# RTS5918 register map
Vendor: Realtek Semiconductor Corp.; Series: RTS5918 Series; File version: 1.00
CPU: ARMV8MML r0p0, little endian, MPU, FPU, VTOR, 3 interrupt priority bits, 8 SAU regions
Registers are 32-bit, read-write, reset 0x0 unless marked. A register's access mark holds for its fields unless they carry their own. Offsets are from the block's base; [hi:lo] are bit positions; {n}, {i} and the like mark numbered series.

## WDT — WDT Controller
Base 0x40253F00
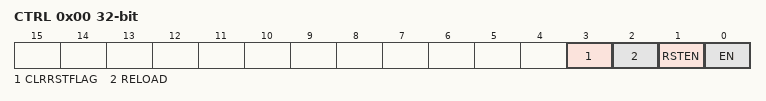
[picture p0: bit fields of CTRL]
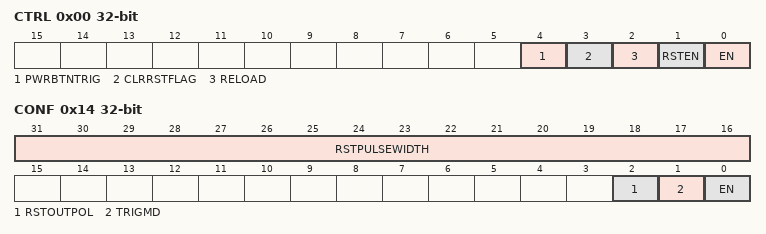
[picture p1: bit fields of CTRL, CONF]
0x00 CTRL — CONTROL REGISTER
  [3] CLRRSTFLAG write-1-clears — Clear WDT reset flag
    0=DO_NOTHING; 1=CLR (Clear WDT reset flag)
  [2] RELOAD — Reload WDT Counter
    0=DO_NOTHING; 1=RELOAD (Reload WDT counter)
  [1] RSTEN — Enable WDT to Reset System
    0=DISABLE (Disable WDT to reset system); 1=ENABLE (Enable WDT to reset system)
  [0] EN — Enable WDT
    0=DISABLE (Disable WDT); 1=ENABLE (Enable WDT)
0x04 STS ro — STATUS REGISTER
  [0] RSTFLAG — Reset Flag
    0=NOT_OCCURRED (WDT reset is not occurred); 1=OCCURRED (WDT reset is occurred)
0x08 CNT — INITIAL COUNTER REGISTER
0x0C DIV — DIVIDER REGISTER
0x10 INTEN — INTERRUPT ENABLE REGISTER
  [0] WDTINTEN — Enable WDT Interrupt
    0=DISBLE (Disable WDT interrupt); 1=ENABLE (Enable WDT interrupt)

## PWRBTN — Power Button Over WDT Controller
Base 0x4000C014
0x00 CTRL — CONTROL REGISTER
  [4] PWRBTNTRIG write-1-clears — Pwrbtn trigger status
    0=DO_NOTHING; 1=CLR (Clear PWRBTN trigger)
  [3] CLRRSTFLAG write-1-clears — Clear WDT reset flag
    0=DO_NOTHING; 1=CLR (Clear WDT reset flag)
  [2] RELOAD — Reload WDT Counter
    0=DO_NOTHING; 1=RELOAD (Reload WDT counter)
  [1] RSTEN — Enable WDT to Reset System
    0=DISABLE (Disable WDT to reset system); 1=ENABLE (Enable WDT to reset system)
  [0] EN — Enable WDT
    0=DISABLE (Disable WDT); 1=ENABLE (Enable WDT)
0x04 STS ro — STATUS REGISTER
  [0] RSTFLAG — Reset Flag
    0=NOT_OCCURRED (WDT reset is not occurred); 1=OCCURRED (WDT reset is occurred)
0x08 CNT — INITIAL COUNTER REGISTER
  [7:0] CNT — Counter value
0x0C DIV — DIVIDER REGISTER
  [15:0] DIV — Divider value
0x10 INTEN — INTERRUPT ENABLE REGISTER
  [0] WDTINTEN — Enable WDT Interrupt
    0=DISBLE (Disable WDT interrupt); 1=ENABLE (Enable WDT interrupt)
0x14 CONF — PWRBTN CONTROL REGISTER
  [31:16] RSTPULSEWIDTH — Reset Output Pulse Width
  [2] RSTOUTPOL — Reset Output Polarity
    0=LOW (Active low); 1=HIGH (Active high)
  [1] TRIGMD — Trigger Level Selection
    0=LOW (Low-level trigger); 1=HIGH (High-level trigger)
  [0] EN — Enable Power Button Function
    0=DISBLE (Disable power button function); 1=ENABLE (Enable power button function)

## SLWTMR0 — 32-bit SlowTimer Controller
Base 0x40253700
Same registers: TMR0 0x40253100, TMR1 0x40253200, TMR2 0x40253300, TMR3 0x40253400, TMR4 0x40253500, TMR5 0x40253600, SLWTMR1 0x40253800, SLWTMR2 0x40253900, SLWTMR3 0x40253A00, RTMR 0x40253B00
0x00 LDCNT — LOAD COUNTER REGISTER
0x04 CNT — CURRENT COUNTER REGISTER
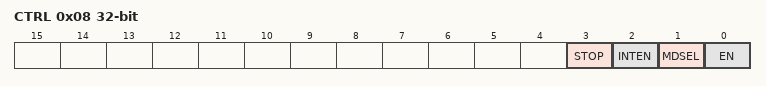
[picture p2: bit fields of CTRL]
0x08 CTRL — CONTROL REGISTER
  [3] STOP — Stop Timer
    0=DISABLE (Start timer); 1=ENABLE (Stop timer)
  [2] INTEN — Enable Timer Interrupt
    0=DISABLE (Disable timer interrupt); 1=ENABLE (Enable timer interrupt)
  [1] MDSEL — Timer Operating Mode Selection
    0=ONE_SHOT (Timer is operate at one-shot mode); 1=CONTINUOUS (Timer is operate at continuous mode)
  [0] EN — Enable Timer Contoller
    0=DISABLE (Disable timer controller); 1=ENABLE (Enable timer controller)
0x0C INTSTS — INTERRUPT STATUS REGISTER
  [0] STS write-1-clears — Timer Interrupt Status
    0=NOT_OCCURRED (Timer interrupt is not occurred); 1=OCCURRED (Timer interrupt is occurred)

## PWM0 — PWM Controller
Base 0x40254500
Same registers: PWM{n} {0x40254500+0x100*n} (n=1..13)
0x00 DUTY — PWM DUTY REGISTER
0x04 DIV — PWM DIVIDER REGISTER
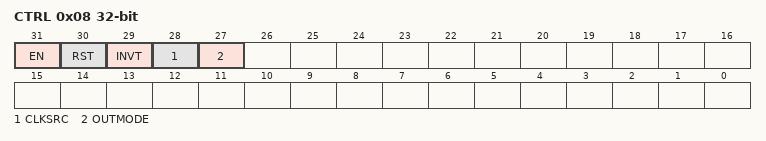
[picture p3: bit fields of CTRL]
0x08 CTRL — PWM CONTROL REGISTER
  [31] EN — Enable PWM Controller
    0=DISABLE (Disable PWM Controller); 1=ENABLE (Enable PWM Controller)
  [30] RST — Reset PWM Controller
    0=DO_NOTHING; 1=RESET (Reset PWM controller)
  [29] INVT — Output Inverter Control
    0=NORMAL (PWM output is not invert); 1=INVERT (PWM output is invert)
  [28] CLKSRC — Clock Source Selection
    0=PLL (PWM clock source is from PLL); 1=RC32K (PWM clock source is from RC32K)
  [27] OUTMODE — Output Mode
    0=OD (Output Mode is Open-Drain); 1=PP (Output Mode is Push-Pull)
